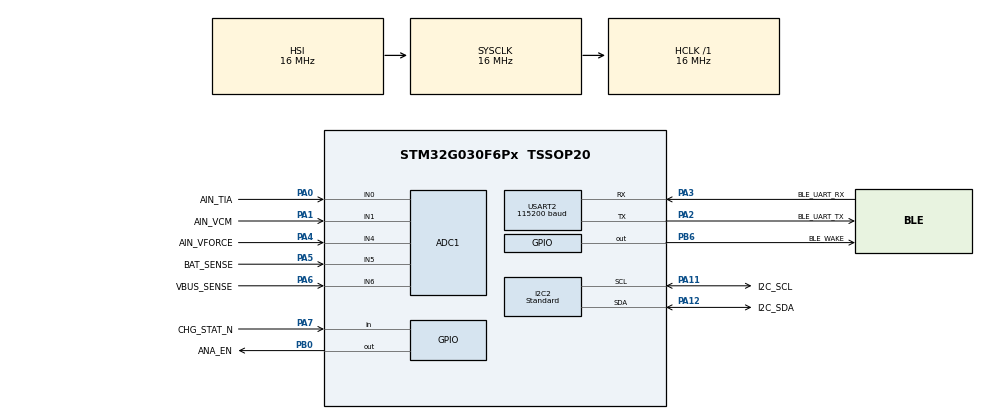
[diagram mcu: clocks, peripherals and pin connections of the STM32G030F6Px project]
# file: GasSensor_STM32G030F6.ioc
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ADC1.Channel-0\#ChannelRegularConversion=ADC_CHANNEL_0
ADC1.Channel-1\#ChannelRegularConversion=ADC_CHANNEL_1
ADC1.Channel-2\#ChannelRegularConversion=ADC_CHANNEL_4
ADC1.Channel-3\#ChannelRegularConversion=ADC_CHANNEL_5
ADC1.Channel-4\#ChannelRegularConversion=ADC_CHANNEL_6
ADC1.Channel-5\#ChannelRegularConversion=ADC_CHANNEL_VREFINT
ADC1.ClockPrescaler=ADC_CLOCK_SYNC_PCLK_DIV4
ADC1.DMAContinuousRequests=ENABLE
ADC1.EOCSelection=ADC_EOC_SEQ_CONV
ADC1.ExternalTrigConv=ADC_EXTERNALTRIG_T3_TRGO
ADC1.ExternalTrigConvEdge=ADC_EXTERNALTRIGCONVEDGE_RISING
ADC1.NbrOfConversion=6
ADC1.NbrOfConversionFlag=1
ADC1.Overrun=ADC_OVR_DATA_OVERWRITTEN
ADC1.OversamplingMode=ENABLE
ADC1.Rank-1\#ChannelRegularConversion=2
ADC1.Rank-2\#ChannelRegularConversion=3
ADC1.Rank-3\#ChannelRegularConversion=4
ADC1.Rank-4\#ChannelRegularConversion=5
ADC1.Rank-5\#ChannelRegularConversion=6
ADC1.Ratio=ADC_OVERSAMPLING_RATIO_64
ADC1.RightBitShift=ADC_RIGHTBITSHIFT_6
ADC1.SamplingTime-0\#ChannelRegularConversion=ADC_SAMPLINGTIME_COMMON_1
ADC1.SamplingTime-1\#ChannelRegularConversion=ADC_SAMPLINGTIME_COMMON_1
ADC1.SamplingTime-2\#ChannelRegularConversion=ADC_SAMPLINGTIME_COMMON_1
ADC1.SamplingTime-3\#ChannelRegularConversion=ADC_SAMPLINGTIME_COMMON_1
ADC1.SamplingTime-4\#ChannelRegularConversion=ADC_SAMPLINGTIME_COMMON_1
ADC1.SamplingTime-5\#ChannelRegularConversion=ADC_SAMPLINGTIME_COMMON_1
ADC1.SamplingTimeCommon1=ADC_SAMPLETIME_160CYCLES_5
ADC1.SelectedChannel=ADC_CHANNEL_0|ADC_CHANNEL_1|ADC_CHANNEL_4|ADC_CHANNEL_5|ADC_CHANNEL_6|ADC_CHANNEL_VREFINT
ADC1.master=1
Dma.ADC1.0.Direction=DMA_PERIPH_TO_MEMORY
Dma.ADC1.0.EventEnable=DISABLE
Dma.ADC1.0.Instance=DMA1_Channel1
Dma.ADC1.0.MemDataAlignment=DMA_MDATAALIGN_HALFWORD
Dma.ADC1.0.MemInc=DMA_MINC_ENABLE
Dma.ADC1.0.Mode=DMA_CIRCULAR
Dma.ADC1.0.PeriphDataAlignment=DMA_PDATAALIGN_HALFWORD
Dma.ADC1.0.PeriphInc=DMA_PINC_DISABLE
Dma.ADC1.0.Polarity=HAL_DMAMUX_REQ_GEN_RISING
Dma.ADC1.0.Priority=DMA_PRIORITY_HIGH
Dma.ADC1.0.RequestNumber=1
Dma.ADC1.0.SignalID=NONE
Dma.ADC1.0.SyncEnable=DISABLE
Dma.ADC1.0.SyncPolarity=HAL_DMAMUX_SYNC_NO_EVENT
Dma.ADC1.0.SyncRequestNumber=1
Dma.ADC1.0.SyncSignalID=NONE
Dma.Request0=ADC1
I2C2.AddressingMode=I2C_ADDRESSINGMODE_7BIT
I2C2.Analog_Filter=I2C_ANALOGFILTER_ENABLE
I2C2.DualAddressMode=I2C_DUALADDRESS_DISABLE
I2C2.GeneralCallMode=I2C_GENERALCALL_DISABLE
I2C2.I2C_Speed_Mode=I2C_Standard
I2C2.NoStretchMode=I2C_NOSTRETCH_DISABLE
I2C2.OwnAddress=0
I2C2.Speed=100
I2C2.Timing=0x00503D58
Mcu.Family=STM32G0
Mcu.Name=STM32G030F6Px
Mcu.Package=TSSOP20
NVIC.DMA1_Channel1_IRQn=true\:1\:0\:false\:false\:true\:false\:true\:true
NVIC.USART2_IRQn=true\:2\:0\:false\:false\:true\:true\:true\:true
PA0.GPIO_Label=AIN_TIA
PA0.Mode=IN0
PA0.Signal=ADC1_IN0
PA1.GPIO_Label=AIN_VCM
PA1.Mode=IN1
PA1.Signal=ADC1_IN1
PA11\ [PA9].GPIO_Label=I2C_SCL
PA11\ [PA9].GPIO_PuPdOD=GPIO_NOPULL
PA11\ [PA9].GPIO_Speed=GPIO_SPEED_FREQ_LOW
PA11\ [PA9].Mode=I2C
PA11\ [PA9].Signal=I2C2_SCL
PA12\ [PA10].GPIO_Label=I2C_SDA
PA12\ [PA10].GPIO_PuPdOD=GPIO_NOPULL
PA12\ [PA10].GPIO_Speed=GPIO_SPEED_FREQ_LOW
PA12\ [PA10].Mode=I2C
PA12\ [PA10].Signal=I2C2_SDA
PA13.Mode=Serial_Wire
PA13.Signal=SYS_SWDIO
PA14-BOOT0.Mode=Serial_Wire
PA14-BOOT0.Signal=SYS_SWCLK
PA14-BOOT0__PA15.StandardMode=true
PA2.GPIO_Label=BLE_UART_TX
PA2.GPIO_Speed=GPIO_SPEED_FREQ_LOW
PA2.Mode=Asynchronous
PA2.Signal=USART2_TX
PA3.GPIO_Label=BLE_UART_RX
PA3.GPIO_Speed=GPIO_SPEED_FREQ_LOW
PA3.Mode=Asynchronous
PA3.Signal=USART2_RX
PA4.GPIO_Label=AIN_VFORCE
PA4.Mode=IN4
PA4.Signal=ADC1_IN4
PA5.GPIO_Label=BAT_SENSE
PA5.Mode=IN5
PA5.Signal=ADC1_IN5
PA6.GPIO_Label=VBUS_SENSE
PA6.Mode=IN6
PA6.Signal=ADC1_IN6
PA7.GPIO_Label=CHG_STAT_N
PA7.GPIO_Mode=GPIO_MODE_INPUT
PA7.GPIO_PuPd=GPIO_NOPULL
PA7.Signal=GPIO_Input
PB0.GPIO_Label=ANA_EN
PB0.GPIO_PuPd=GPIO_NOPULL
PB0.GPIO_Speed=GPIO_SPEED_FREQ_LOW
PB0.PinState=GPIO_PIN_RESET
PB0.Signal=GPIO_Output
PB0__PB1__PB2__PA8.StandardMode=true
PB3__PB4__PB5__PB6.StandardMode=true
PB6.GPIO_Label=BLE_WAKE
PB6.GPIO_PuPd=GPIO_NOPULL
PB6.GPIO_Speed=GPIO_SPEED_FREQ_LOW
PB6.PinState=GPIO_PIN_SET
PB6.Signal=GPIO_Output
PB7__PB8.StandardMode=true
PC14-OSC32_IN\ (PC14)__PB9.StandardMode=true
ProjectManager.HeapSize=0x200
ProjectManager.StackSize=0x400
ProjectManager.TargetToolchain=MDK-ARM V5.32
RCC.ADCFreq_Value=16000000
RCC.AHBFreq_Value=16000000
RCC.CortexFreq_Value=16000000
RCC.EXTERNAL_CLOCK_VALUE=12288000
RCC.HCLKFreq_Value=16000000
RCC.HSE_VALUE=8000000
RCC.HSI_VALUE=16000000
RCC.LSE_VALUE=32768
RCC.SYSCLKFreq_VALUE=16000000
RCC.VCOOutputFreq_Value=128000000
RCC.VDD_VALUE=3
TIM3.Period=49
TIM3.Prescaler=15999
TIM3.TIM_MasterOutputTrigger=TIM_TRGO_UPDATE
USART2.BaudRate=115200
USART2.Parity=PARITY_NONE
USART2.StopBits=STOPBITS_1
USART2.VirtualMode-Asynchronous=VM_ASYNC
USART2.WordLength=WORDLENGTH_8B
VP_ADC1_Vref_Input.Mode=IN-Vrefint
VP_TIM3_VS_ClockSourceINT.Mode=Internal
board=custom

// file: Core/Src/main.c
/* USER CODE BEGIN Header */
/**
  ******************************************************************************
  * @file           : main.c
  * @brief          : Main program body
  ******************************************************************************
  * @attention
  *
  * Copyright (c) 2026 STMicroelectronics.
  * All rights reserved.
  *
  * This software is licensed under terms that can be found in the LICENSE file
  * in the root directory of this software component.
  * If no LICENSE file comes with this software, it is provided AS-IS.
  *
  ******************************************************************************
  */
/* USER CODE END Header */
#include "main.h"
#include "adc.h"
#include "dma.h"
#include "i2c.h"
#include "tim.h"
#include "usart.h"
#include "gpio.h"

/* USER CODE BEGIN Includes */
#include "gas_sensor.h"
/* USER CODE END Includes */

void SystemClock_Config(void);

int main(void)
{

  /* MCU Configuration--------------------------------------------------------*/

  /* Reset of all peripherals, Initializes the Flash interface and the Systick. */
  HAL_Init();

  /* Configure the system clock */
  SystemClock_Config();

  /* Initialize all configured peripherals */
  MX_GPIO_Init();
  MX_DMA_Init();
  MX_I2C2_Init();
  MX_USART2_UART_Init();
  MX_TIM3_Init();
  MX_ADC1_Init();
  /* USER CODE BEGIN 2 */
  if (GasSensor_Init() != HAL_OK)
  {
    Error_Handler();
  }
  /* USER CODE END 2 */

  /* Infinite loop */
  while (1)
  {

    /* USER CODE BEGIN 3 */
    GasSensor_Process();
  }
  /* USER CODE END 3 */
}

void SystemClock_Config(void)
{
  RCC_OscInitTypeDef RCC_OscInitStruct = {0};
  RCC_ClkInitTypeDef RCC_ClkInitStruct = {0};

  /** Configure the main internal regulator output voltage
  */
  HAL_PWREx_ControlVoltageScaling(PWR_REGULATOR_VOLTAGE_SCALE1);

  /** Initializes the RCC Oscillators according to the specified parameters
  * in the RCC_OscInitTypeDef structure.
  */
  RCC_OscInitStruct.OscillatorType = RCC_OSCILLATORTYPE_HSI;
  RCC_OscInitStruct.HSIState = RCC_HSI_ON;
  RCC_OscInitStruct.HSIDiv = RCC_HSI_DIV1;
  RCC_OscInitStruct.HSICalibrationValue = RCC_HSICALIBRATION_DEFAULT;
  RCC_OscInitStruct.PLL.PLLState = RCC_PLL_NONE;
  if (HAL_RCC_OscConfig(&RCC_OscInitStruct) != HAL_OK)
  {
    Error_Handler();
  }

  /** Initializes the CPU, AHB and APB buses clocks
  */
  RCC_ClkInitStruct.ClockType = RCC_CLOCKTYPE_HCLK|RCC_CLOCKTYPE_SYSCLK
                              |RCC_CLOCKTYPE_PCLK1;
  RCC_ClkInitStruct.SYSCLKSource = RCC_SYSCLKSOURCE_HSI;
  RCC_ClkInitStruct.AHBCLKDivider = RCC_SYSCLK_DIV1;
  RCC_ClkInitStruct.APB1CLKDivider = RCC_HCLK_DIV1;

  if (HAL_RCC_ClockConfig(&RCC_ClkInitStruct, FLASH_LATENCY_0) != HAL_OK)
  {
    Error_Handler();
  }
}

void Error_Handler(void)
{
  /* USER CODE BEGIN Error_Handler_Debug */
  GasSensor_ForceSafeOff();
  __disable_irq();
  while (1)
  {
  }
  /* USER CODE END Error_Handler_Debug */
}
